AUTOSAR XML (schema 4-2-2)
package /Components
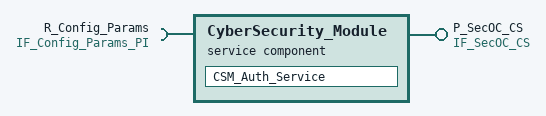
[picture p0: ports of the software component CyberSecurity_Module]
  service sw component type CyberSecurity_Module
    provide port P_SecOC_CS: provided-interface=IF_SecOC_CS
    require port R_Config_Params: required-interface=IF_Config_Params_PI
    behavior CyberSecurity_Module_InternalBehavior
      init event CSM_InitEvent: start-on-event=CSM_Auth_Service
      operation invoked event CSM_ServiceInvoked: start-on-event=CSM_Auth_Service
      runnable CSM_Auth_Service: can-be-invoked-concurrently=true
        parameter access Access_Security_Policy: accessed-parameter=R_Config_Params.security_policy
        parameter access Access_Key_Ref: accessed-parameter=R_Config_Params.key_ref
